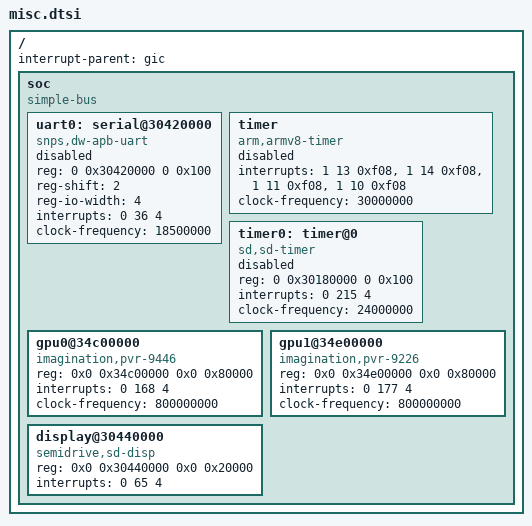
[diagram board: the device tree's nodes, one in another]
/*
 * Semidrive kunlun platform DTS file
 *
 * Copyright (C) 2019, Semidrive  Communications Inc.
 *
 * This file is licensed under a dual GPLv2 or X11 license.
 */

/ {
	interrupt-parent = <&gic>;
	#address-cells = <2>;
	#size-cells = <2>;

	soc {
		compatible = "simple-bus";
		#address-cells = <2>;
		#size-cells = <2>;
		ranges;

		uart0: serial@30420000 {
			compatible = "snps,dw-apb-uart";
			reg = <0 0x30420000 0 0x100>;
			reg-shift=<2>;
			reg-io-width=<4>;
			interrupts = <0 36 4>;
			clock-frequency=<18500000>;
			status = "disabled";
		};

		timer {
			compatible = "arm,armv8-timer";
			interrupts = <1 13 0xf08>,
				<1 14 0xf08>,
				<1 11 0xf08>,
				<1 10 0xf08>;
			clock-frequency = <30000000>;
			status = "disabled";
		};

		timer0: timer@0 {
			compatible = "sd,sd-timer";
			#address-cells = <2>;
			#size-cells = <2>;
			reg = <0 0x30180000 0 0x100>;
			interrupts = <0 215 4>;
			clock-frequency = <24000000>;
			status = "disabled";
		};
                gpu0@34c00000 {
                        compatible = "imagination,pvr-9446";
                        reg = <0x0 0x34c00000 0x0 0x80000>;
                        interrupts = <0 168 4>;
                        clock-frequency = <800000000>;
                        status = "okay";
                };
                gpu1@34e00000 {
                        compatible = "imagination,pvr-9226";
                        reg = <0x0 0x34e00000 0x0 0x80000>;
                        interrupts = <0 177 4>;
                        clock-frequency = <800000000>;
                        status = "okay";
                };
				display@30440000 {
					compatible = "semidrive,sd-disp";
					reg = <0x0 0x30440000 0x0 0x20000>;
					interrupts = <0 65 4>;
					status = "okay";
				};

	};
};
